# ESP32-P4-LP register map
Vendor: ESPRESSIF SYSTEMS (SHANGHAI) CO., LTD.; Series: ESP32 P-Series; File version: 3
CPU: RV32IMAC r0p0, little endian, no MPU, no FPU, 0 interrupt priority bits
Address unit: 32 bits
Registers are 32-bit, read-write, reset 0x0 unless marked. A register's access mark holds for its fields unless they carry their own. Offsets are from the block's base; [hi:lo] are bit positions; {n}, {i} and the like mark numbered series.

## LP_AON_CLKRST — LP_AON_CLKRST Peripheral
Base 0x50111000
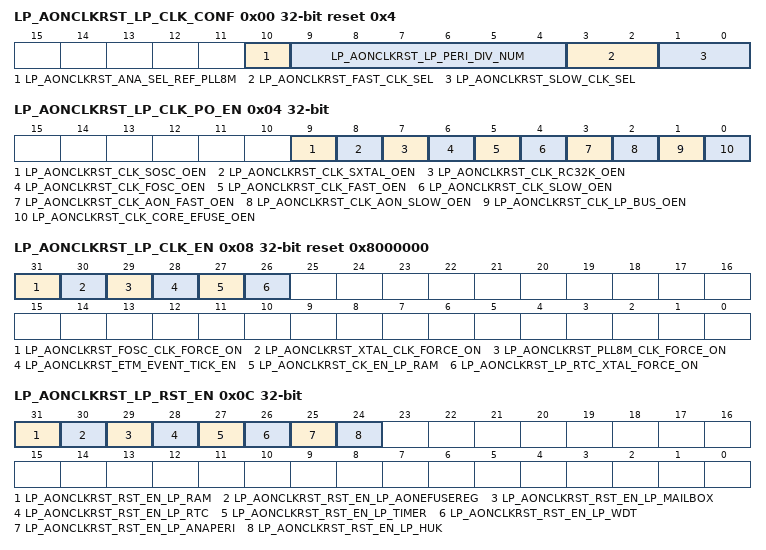
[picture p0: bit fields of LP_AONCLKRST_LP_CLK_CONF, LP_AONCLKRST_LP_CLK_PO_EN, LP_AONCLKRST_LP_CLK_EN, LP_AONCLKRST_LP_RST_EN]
0x00 LP_AONCLKRST_LP_CLK_CONF reset 0x4 — need_des
  [10] LP_AONCLKRST_ANA_SEL_REF_PLL8M — need_des
  [9:4] LP_AONCLKRST_LP_PERI_DIV_NUM — need_des
  [3:2] LP_AONCLKRST_FAST_CLK_SEL — need_des
  [1:0] LP_AONCLKRST_SLOW_CLK_SEL — need_des
0x04 LP_AONCLKRST_LP_CLK_PO_EN — need_des
  [9] LP_AONCLKRST_CLK_SOSC_OEN — 1'b1: probe sosc clk on 1'b0: probe sosc clk off
  [8] LP_AONCLKRST_CLK_SXTAL_OEN — need_des
  [7] LP_AONCLKRST_CLK_RC32K_OEN — need_des
  [6] LP_AONCLKRST_CLK_FOSC_OEN — need_des
  [5] LP_AONCLKRST_CLK_FAST_OEN — need_des
  [4] LP_AONCLKRST_CLK_SLOW_OEN — need_des
  [3] LP_AONCLKRST_CLK_AON_FAST_OEN — need_des
  [2] LP_AONCLKRST_CLK_AON_SLOW_OEN — need_des
  [1] LP_AONCLKRST_CLK_LP_BUS_OEN — need_des
  [0] LP_AONCLKRST_CLK_CORE_EFUSE_OEN — need_des
0x08 LP_AONCLKRST_LP_CLK_EN reset 0x8000000 — need_des
  [31] LP_AONCLKRST_FOSC_CLK_FORCE_ON — need_des
  [30] LP_AONCLKRST_XTAL_CLK_FORCE_ON — need_des
  [29] LP_AONCLKRST_PLL8M_CLK_FORCE_ON — need_des
  [28] LP_AONCLKRST_ETM_EVENT_TICK_EN — need_des
  [27] LP_AONCLKRST_CK_EN_LP_RAM — need_des
  [26] LP_AONCLKRST_LP_RTC_XTAL_FORCE_ON — need_des
0x0C LP_AONCLKRST_LP_RST_EN — need_des
  [31] LP_AONCLKRST_RST_EN_LP_RAM — need_des
  [30] LP_AONCLKRST_RST_EN_LP_AONEFUSEREG — need_des
  [29] LP_AONCLKRST_RST_EN_LP_MAILBOX — need_des
  [28] LP_AONCLKRST_RST_EN_LP_RTC — need_des
  [27] LP_AONCLKRST_RST_EN_LP_TIMER — need_des
  [26] LP_AONCLKRST_RST_EN_LP_WDT — need_des
  [25] LP_AONCLKRST_RST_EN_LP_ANAPERI — need_des
  [24] LP_AONCLKRST_RST_EN_LP_HUK — need_des
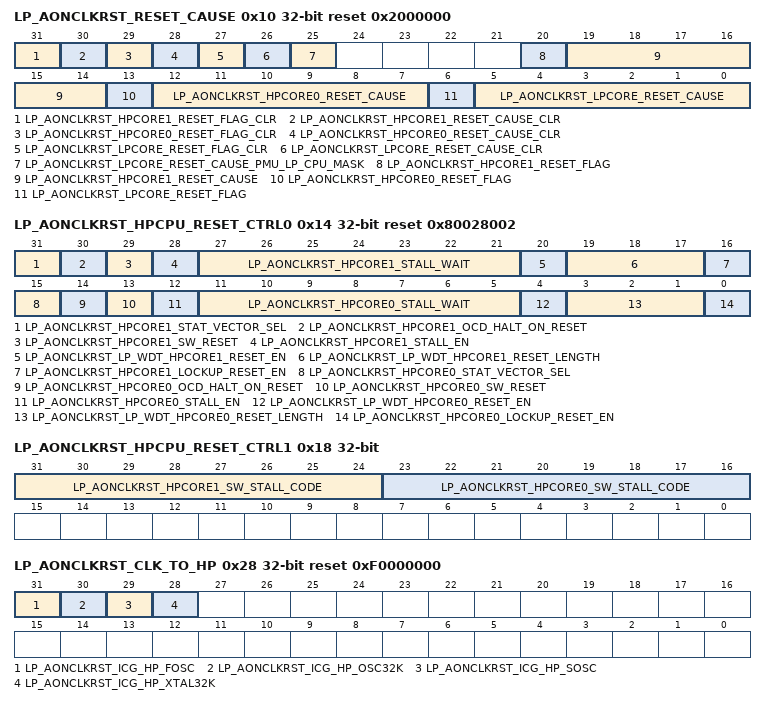
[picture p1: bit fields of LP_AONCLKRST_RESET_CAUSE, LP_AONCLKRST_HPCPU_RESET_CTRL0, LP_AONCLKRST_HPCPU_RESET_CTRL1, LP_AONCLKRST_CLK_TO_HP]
0x10 LP_AONCLKRST_RESET_CAUSE access per field reset 0x2000000 — need_des
  [31] LP_AONCLKRST_HPCORE1_RESET_FLAG_CLR wo — need_des
  [30] LP_AONCLKRST_HPCORE1_RESET_CAUSE_CLR wo — need_des
  [29] LP_AONCLKRST_HPCORE0_RESET_FLAG_CLR wo — need_des
  [28] LP_AONCLKRST_HPCORE0_RESET_CAUSE_CLR wo — need_des
  [27] LP_AONCLKRST_LPCORE_RESET_FLAG_CLR wo — need_des
  [26] LP_AONCLKRST_LPCORE_RESET_CAUSE_CLR wo — need_des
  [25] LP_AONCLKRST_LPCORE_RESET_CAUSE_PMU_LP_CPU_MASK rw — 1'b0: enable lpcore pmu_lp_cpu_reset reset_cause, 1'b1: disable lpcore pmu_lp_cpu_reset reset_cause
  [20] LP_AONCLKRST_HPCORE1_RESET_FLAG ro — need_des
  [19:14] LP_AONCLKRST_HPCORE1_RESET_CAUSE ro — 6'h1: POR reset 6'h3: digital system software reset 6'h5: PMU HP system power down reset 6'h7: HP system reset from HP watchdog 6'h9: HP system reset from LP watchdog 6'hb: HP core reset from HP watchdog 6'hc: HP core software reset 6'hd: HP core reset from LP watchdog 6'hf: brown out reset 6'h10: LP watchdog chip reset 6'h12: super watch dog reset 6'h13: glitch reset 6'h14: efuse crc error reset 6'h16: HP usb jtag chip reset 6'h17: HP usb uart chip reset 6'h18: HP jtag reset 6'h1a: HP core lockup
  [13] LP_AONCLKRST_HPCORE0_RESET_FLAG ro — need_des
  [12:7] LP_AONCLKRST_HPCORE0_RESET_CAUSE ro — 6'h1: POR reset 6'h3: digital system software reset 6'h5: PMU HP system power down reset 6'h7: HP system reset from HP watchdog 6'h9: HP system reset from LP watchdog 6'hb: HP core reset from HP watchdog 6'hc: HP core software reset 6'hd: HP core reset from LP watchdog 6'hf: brown out reset 6'h10: LP watchdog chip reset 6'h12: super watch dog reset 6'h13: glitch reset 6'h14: efuse crc error reset 6'h16: HP usb jtag chip reset 6'h17: HP usb uart chip reset 6'h18: HP jtag reset 6'h1a: HP core lockup
  [6] LP_AONCLKRST_LPCORE_RESET_FLAG ro — need_des
  [5:0] LP_AONCLKRST_LPCORE_RESET_CAUSE ro — 6'h1: POR reset 6'h9: PMU LP PERI power down reset 6'ha: PMU LP CPU reset 6'hf: brown out reset 6'h10: LP watchdog chip reset 6'h12: super watch dog reset 6'h13: glitch reset 6'h14: software reset
0x14 LP_AONCLKRST_HPCPU_RESET_CTRL0 access per field reset 0x80028002 — need_des
  [31] LP_AONCLKRST_HPCORE1_STAT_VECTOR_SEL rw — 1'b1: boot from HP TCM ROM: 0x4FC00000 1'b0: boot from LP TCM RAM: 0x50108000
  [30] LP_AONCLKRST_HPCORE1_OCD_HALT_ON_RESET rw — need_des
  [29] LP_AONCLKRST_HPCORE1_SW_RESET wo — need_des
  [28] LP_AONCLKRST_HPCORE1_STALL_EN rw — need_des
  [27:21] LP_AONCLKRST_HPCORE1_STALL_WAIT rw — need_des
  [20] LP_AONCLKRST_LP_WDT_HPCORE1_RESET_EN rw — write 1 to enable lp_wdt reset hpcore1 feature, write 0 to disable lp_wdt reset hpcore1 feature
  [19:17] LP_AONCLKRST_LP_WDT_HPCORE1_RESET_LENGTH rw — need_des
  [16] LP_AONCLKRST_HPCORE1_LOCKUP_RESET_EN rw — write 1 to enable hpcore1 lockup reset feature, write 0 to disable hpcore1 lockup reset feature
  [15] LP_AONCLKRST_HPCORE0_STAT_VECTOR_SEL rw — 1'b1: boot from HP TCM ROM: 0x4FC00000 1'b0: boot from LP TCM RAM: 0x50108000
  [14] LP_AONCLKRST_HPCORE0_OCD_HALT_ON_RESET rw — need_des
  [13] LP_AONCLKRST_HPCORE0_SW_RESET wo — need_des
  [12] LP_AONCLKRST_HPCORE0_STALL_EN rw — need_des
  [11:5] LP_AONCLKRST_HPCORE0_STALL_WAIT rw — need_des
  [4] LP_AONCLKRST_LP_WDT_HPCORE0_RESET_EN rw — write 1 to enable lp_wdt reset hpcore0 feature, write 0 to disable lp_wdt reset hpcore0 feature
  [3:1] LP_AONCLKRST_LP_WDT_HPCORE0_RESET_LENGTH rw — need_des
  [0] LP_AONCLKRST_HPCORE0_LOCKUP_RESET_EN rw — write 1 to enable hpcore0 lockup reset feature, write 0 to disable hpcore0 lockup reset feature
0x18 LP_AONCLKRST_HPCPU_RESET_CTRL1 — need_des
  [31:24] LP_AONCLKRST_HPCORE1_SW_STALL_CODE — HP core1 software stall when set to 8'h86
  [23:16] LP_AONCLKRST_HPCORE0_SW_STALL_CODE — HP core0 software stall when set to 8'h86
0x1C LP_AONCLKRST_FOSC_CNTL reset 0x64000000 — need_des
  [31:22] LP_AONCLKRST_FOSC_DFREQ
0x20 LP_AONCLKRST_RC32K_CNTL reset 0x28A — need_des
  [31:0] LP_AONCLKRST_RC32K_DFREQ
0x24 LP_AONCLKRST_SOSC_CNTL reset 0x2B000000 — need_des
  [31:22] LP_AONCLKRST_SOSC_DFREQ
0x28 LP_AONCLKRST_CLK_TO_HP reset 0xF0000000 — need_des
  [31] LP_AONCLKRST_ICG_HP_FOSC — reserved
  [30] LP_AONCLKRST_ICG_HP_OSC32K — reserved
  [29] LP_AONCLKRST_ICG_HP_SOSC — reserved
  [28] LP_AONCLKRST_ICG_HP_XTAL32K — reserved
0x2C LP_AONCLKRST_LPMEM_FORCE — need_des
  [31] LP_AONCLKRST_LPMEM_CLK_FORCE_ON — reserved
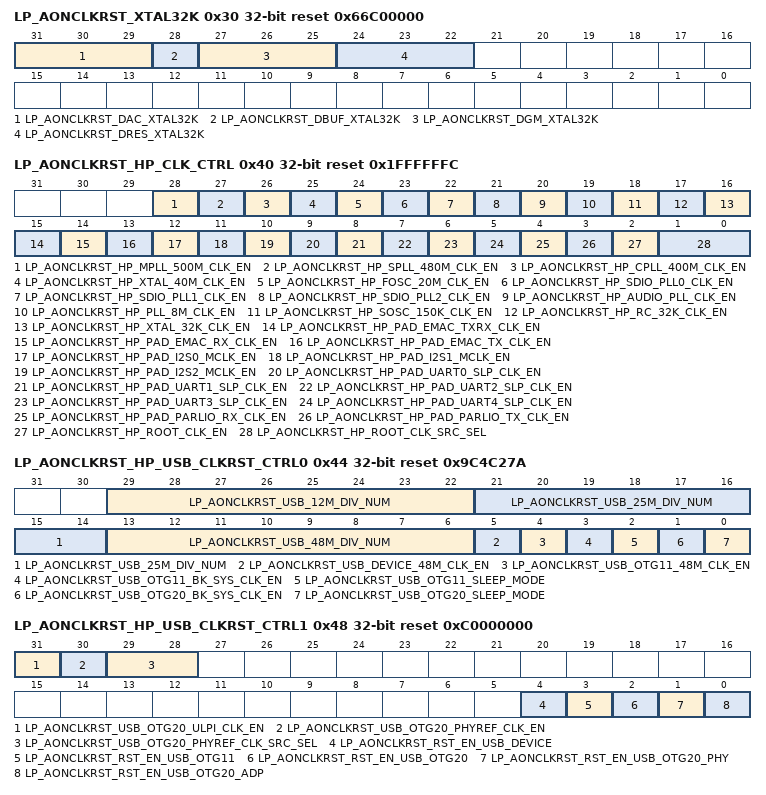
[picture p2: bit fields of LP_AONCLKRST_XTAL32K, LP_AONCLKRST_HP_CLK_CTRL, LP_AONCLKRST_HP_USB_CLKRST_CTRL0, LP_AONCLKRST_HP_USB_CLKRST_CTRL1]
0x30 LP_AONCLKRST_XTAL32K reset 0x66C00000 — need_des
  [31:29] LP_AONCLKRST_DAC_XTAL32K — need_des
  [28] LP_AONCLKRST_DBUF_XTAL32K — need_des
  [27:25] LP_AONCLKRST_DGM_XTAL32K — need_des
  [24:22] LP_AONCLKRST_DRES_XTAL32K — need_des
0x34 LP_AONCLKRST_MUX_HPSYS_RESET_BYPASS reset 0xFFFFFFFF — need_des
  [31:0] LP_AONCLKRST_MUX_HPSYS_RESET_BYPASS — reserved
0x38 LP_AONCLKRST_HPSYS_0_RESET_BYPASS reset 0xFFFFFFFF — need_des
  [31:0] LP_AONCLKRST_HPSYS_0_RESET_BYPASS — reserved
0x3C LP_AONCLKRST_HPSYS_APM_RESET_BYPASS reset 0xFFFFFFFF — need_des
  [31:0] LP_AONCLKRST_HPSYS_APM_RESET_BYPASS — reserved
0x40 LP_AONCLKRST_HP_CLK_CTRL reset 0x1FFFFFFC — HP Clock Control Register.
  [28] LP_AONCLKRST_HP_MPLL_500M_CLK_EN — MPLL 500M Clock Enable.
  [27] LP_AONCLKRST_HP_SPLL_480M_CLK_EN — SPLL 480M Clock Enable.
  [26] LP_AONCLKRST_HP_CPLL_400M_CLK_EN — CPLL 400M Clock Enable.
  [25] LP_AONCLKRST_HP_XTAL_40M_CLK_EN — XTAL 40M Clock Enalbe.
  [24] LP_AONCLKRST_HP_FOSC_20M_CLK_EN — FOSC 20M Clock Enable.
  [23] LP_AONCLKRST_HP_SDIO_PLL0_CLK_EN — SDIO PLL0 Clock Enable.
  [22] LP_AONCLKRST_HP_SDIO_PLL1_CLK_EN — SDIO PLL1 Clock Enable.
  [21] LP_AONCLKRST_HP_SDIO_PLL2_CLK_EN — SDIO PLL2 Clock Enable.
  [20] LP_AONCLKRST_HP_AUDIO_PLL_CLK_EN — AUDIO PLL Clock Enable.
  [19] LP_AONCLKRST_HP_PLL_8M_CLK_EN — PLL 8M Clock Enable.
  [18] LP_AONCLKRST_HP_SOSC_150K_CLK_EN — SOSC 150K Clock Enable.
  [17] LP_AONCLKRST_HP_RC_32K_CLK_EN — RC 32K Clock Enable.
  [16] LP_AONCLKRST_HP_XTAL_32K_CLK_EN — XTAL 32K Clock Enable.
  [15] LP_AONCLKRST_HP_PAD_EMAC_TXRX_CLK_EN — EMAC TXRX Clock From Pad Enable.
  [14] LP_AONCLKRST_HP_PAD_EMAC_RX_CLK_EN — EMAC TX Clock From Pad Enable.
  [13] LP_AONCLKRST_HP_PAD_EMAC_TX_CLK_EN — EMAC RX Clock From Pad Enable.
  [12] LP_AONCLKRST_HP_PAD_I2S0_MCLK_EN — I2S0 MCLK Clock From Pad Enable.
  [11] LP_AONCLKRST_HP_PAD_I2S1_MCLK_EN — I2S1 MCLK Clock From Pad Enable.
  [10] LP_AONCLKRST_HP_PAD_I2S2_MCLK_EN — I2S2 MCLK Clock From Pad Enable.
  [9-n] LP_AONCLKRST_HP_PAD_UART{n}_SLP_CLK_EN (n=0..4) — UART{n} SLP Clock From Pad Enable.
  [4] LP_AONCLKRST_HP_PAD_PARLIO_RX_CLK_EN — PARLIO RX Clock From Pad Enable.
  [3] LP_AONCLKRST_HP_PAD_PARLIO_TX_CLK_EN — PARLIO TX Clock From Pad Enable.
  [2] LP_AONCLKRST_HP_ROOT_CLK_EN — HP SoC Root Clock Enable.
  [1:0] LP_AONCLKRST_HP_ROOT_CLK_SRC_SEL — HP SoC Root Clock Source Select. 2'd0: xtal_40m, 2'd1: cpll_400m, 2'd2: fosc_20m.
0x44 LP_AONCLKRST_HP_USB_CLKRST_CTRL0 reset 0x9C4C27A — HP USB Clock Reset Control Register.
  [29:22] LP_AONCLKRST_USB_12M_DIV_NUM — usb 480m to 12m divide number.
  [21:14] LP_AONCLKRST_USB_25M_DIV_NUM — usb 500m to 25m divide number.
  [13:6] LP_AONCLKRST_USB_48M_DIV_NUM — usb 480m to 25m divide number.
  [5] LP_AONCLKRST_USB_DEVICE_48M_CLK_EN — usb device fs phy clock enable.
  [4] LP_AONCLKRST_USB_OTG11_48M_CLK_EN — usb otg11 fs phy clock enable.
  [3] LP_AONCLKRST_USB_OTG11_BK_SYS_CLK_EN — unused.
  [2] LP_AONCLKRST_USB_OTG11_SLEEP_MODE — unused.
  [1] LP_AONCLKRST_USB_OTG20_BK_SYS_CLK_EN — unused.
  [0] LP_AONCLKRST_USB_OTG20_SLEEP_MODE — unused.
0x48 LP_AONCLKRST_HP_USB_CLKRST_CTRL1 reset 0xC0000000 — HP USB Clock Reset Control Register.
  [31] LP_AONCLKRST_USB_OTG20_ULPI_CLK_EN — usb otg20 ulpi clock enable.
  [30] LP_AONCLKRST_USB_OTG20_PHYREF_CLK_EN — usb otg20 hs phy refclk enable.
  [29:28] LP_AONCLKRST_USB_OTG20_PHYREF_CLK_SRC_SEL — usb otg20 hs phy src sel. 2'd0: 12m, 2'd1: 25m, 2'd2: pad_hsphy_refclk.
  [4] LP_AONCLKRST_RST_EN_USB_DEVICE — usb device reset en
  [3] LP_AONCLKRST_RST_EN_USB_OTG11 — usb org11 reset en
  [2] LP_AONCLKRST_RST_EN_USB_OTG20 — usb otg20 reset en
  [1] LP_AONCLKRST_RST_EN_USB_OTG20_PHY — usb otg20 phy reset en
  [0] LP_AONCLKRST_RST_EN_USB_OTG20_ADP — usb otg20 adp reset en
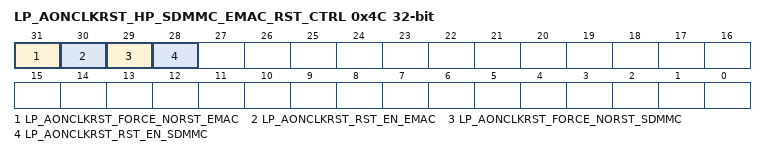
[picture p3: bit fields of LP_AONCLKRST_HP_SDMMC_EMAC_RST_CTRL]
0x4C LP_AONCLKRST_HP_SDMMC_EMAC_RST_CTRL — need_des
  [31] LP_AONCLKRST_FORCE_NORST_EMAC — hp emac force norst
  [30] LP_AONCLKRST_RST_EN_EMAC — hp emac reset en
  [29] LP_AONCLKRST_FORCE_NORST_SDMMC — hp sdmmc force norst
  [28] LP_AONCLKRST_RST_EN_SDMMC — hp sdmmc reset en
0x3FC LP_AONCLKRST_DATE — need_des
  [31] LP_AONCLKRST_CLK_EN
